VERSION ""

NS_ :

BS_:

BU_: New_Node_1

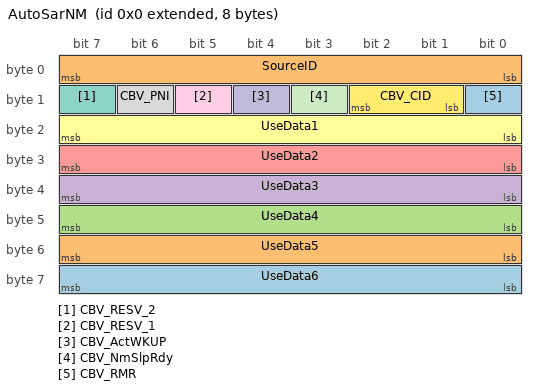
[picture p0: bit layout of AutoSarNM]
BO_ 2147483648 AutoSarNM: 8 Vector__XXX
 SG_ UseData6 : 63|8@0+ (1,0) [0|0] "" Vector__XXX
 SG_ UseData5 : 55|8@0+ (1,0) [0|0] "" Vector__XXX
 SG_ UseData4 : 47|8@0+ (1,0) [0|0] "" Vector__XXX
 SG_ UseData3 : 39|8@0+ (1,0) [0|0] "" Vector__XXX
 SG_ UseData2 : 31|8@0+ (1,0) [0|0] "" Vector__XXX
 SG_ UseData1 : 23|8@0+ (1,0) [0|0] "" Vector__XXX
 SG_ CBV_RESV_2 : 15|1@0+ (1,0) [0|0] "" Vector__XXX
 SG_ CBV_PNI : 14|1@0+ (1,0) [0|0] "" Vector__XXX
 SG_ CBV_RESV_1 : 13|1@0+ (1,0) [0|0] "" Vector__XXX
 SG_ CBV_ActWKUP : 12|1@0+ (1,0) [0|0] "" Vector__XXX
 SG_ CBV_NmSlpRdy : 11|1@0+ (1,0) [0|0] "" Vector__XXX
 SG_ CBV_CID : 10|2@0+ (1,0) [0|0] "" Vector__XXX
 SG_ CBV_RMR : 8|1@0+ (1,0) [0|0] "" Vector__XXX
 SG_ SourceID : 7|8@0+ (1,0) [0|0] "" Vector__XXX

BA_DEF_ BO_  "CANFD_BRS" ENUM  "0","1";
BA_DEF_  "DBName" STRING ;
BA_DEF_  "BusType" STRING ;
BA_DEF_ BO_  "VFrameFormat" ENUM  "StandardCAN","ExtendedCAN","reserved","reserved","reserved","reserved","reserved","reserved","reserved","reserved","reserved","reserved","reserved","reserved","StandardCAN_FD","ExtendedCAN_FD";
BA_DEF_DEF_  "CANFD_BRS" "1";
BA_DEF_DEF_  "DBName" "";
BA_DEF_DEF_  "BusType" "";
BA_DEF_DEF_  "VFrameFormat" "StandardCAN";
BA_ "BusType" "CAN FD";
BA_ "DBName" "S32K344_DEMO";
BA_ "VFrameFormat" BO_ 2147483648 15;
